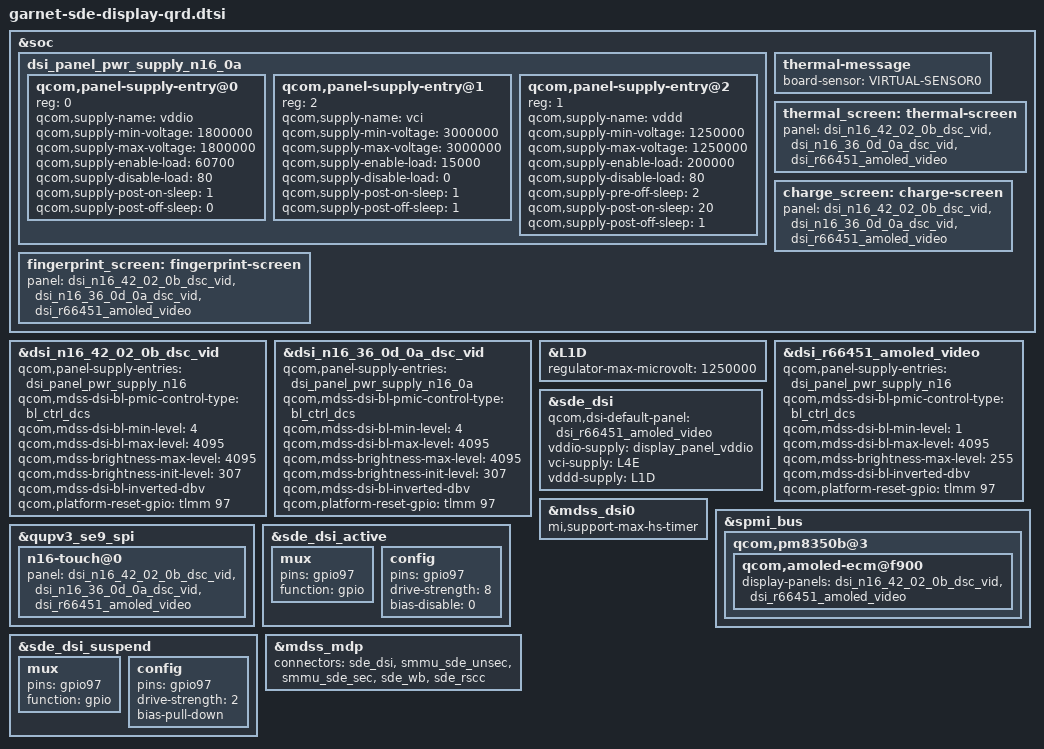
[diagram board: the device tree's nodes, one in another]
#include "parrot-sde-display.dtsi"

&soc {
	dsi_panel_pwr_supply_n16_0a: dsi_panel_pwr_supply_n16_0a {
		#address-cells = <1>;
		#size-cells = <0>;
		qcom,panel-supply-entry@0 {
			reg = <0>;
			qcom,supply-name = "vddio";
			qcom,supply-min-voltage = <1800000>;
			qcom,supply-max-voltage = <1800000>;
			qcom,supply-enable-load = <60700>;
			qcom,supply-disable-load = <80>;
			qcom,supply-post-on-sleep = <1>;
			qcom,supply-post-off-sleep = <0>;
		};
		qcom,panel-supply-entry@1 {
			reg = <2>;
			qcom,supply-name = "vci";
			qcom,supply-min-voltage = <3000000>;
			qcom,supply-max-voltage = <3000000>;
			qcom,supply-enable-load = <15000>;
			qcom,supply-disable-load = <0>;
			qcom,supply-post-on-sleep = <1>;
			qcom,supply-post-off-sleep = <1>;
		};
		qcom,panel-supply-entry@2 {
			reg = <1>;
			qcom,supply-name = "vddd";
			qcom,supply-min-voltage = <1250000>;
			qcom,supply-max-voltage = <1250000>;
			qcom,supply-enable-load = <200000>;
			qcom,supply-disable-load = <80>;
			qcom,supply-pre-off-sleep = <2>;
			qcom,supply-post-on-sleep = <20>;
			qcom,supply-post-off-sleep = <1>;
		};
	};
};

&dsi_n16_42_02_0b_dsc_vid {
	qcom,panel-supply-entries = <&dsi_panel_pwr_supply_n16>;
	qcom,mdss-dsi-bl-pmic-control-type = "bl_ctrl_dcs";
	qcom,mdss-dsi-bl-min-level = <4>;
	qcom,mdss-dsi-bl-max-level = <4095>;
	qcom,mdss-brightness-max-level = <4095>;
	qcom,mdss-brightness-init-level = <307>;
	qcom,mdss-dsi-bl-inverted-dbv;
	qcom,platform-reset-gpio = <&tlmm 97 0>;
};

&dsi_n16_36_0d_0a_dsc_vid {
	qcom,panel-supply-entries = <&dsi_panel_pwr_supply_n16_0a>;
	qcom,mdss-dsi-bl-pmic-control-type = "bl_ctrl_dcs";
	qcom,mdss-dsi-bl-min-level = <4>;
	qcom,mdss-dsi-bl-max-level = <4095>;
	qcom,mdss-brightness-max-level = <4095>;
	qcom,mdss-brightness-init-level = <307>;
	qcom,mdss-dsi-bl-inverted-dbv;
	qcom,platform-reset-gpio = <&tlmm 97 0>;
};

&L1D {
    regulator-max-microvolt = <1250000>;
};

&dsi_r66451_amoled_video {
	qcom,panel-supply-entries = <&dsi_panel_pwr_supply_n16>;
	qcom,mdss-dsi-bl-pmic-control-type = "bl_ctrl_dcs";
	qcom,mdss-dsi-bl-min-level = <1>;
	qcom,mdss-dsi-bl-max-level = <4095>;
	qcom,mdss-brightness-max-level = <255>;
	qcom,mdss-dsi-bl-inverted-dbv;
	qcom,platform-reset-gpio = <&tlmm 97 0>;
};

&sde_dsi {
	qcom,dsi-default-panel = <&dsi_r66451_amoled_video>;
	vddio-supply = <&display_panel_vddio>;
	vci-supply = <&L4E>;
	vddd-supply = <&L1D>;
};

&mdss_dsi0 {
	mi,support-max-hs-timer;
};

&spmi_bus {
	qcom,pm8350b@3 {
		qcom,amoled-ecm@f900 {
			display-panels = <&dsi_n16_42_02_0b_dsc_vid
					&dsi_r66451_amoled_video>;
		};
	};
};

&qupv3_se9_spi {
	n16-touch@0 {
		panel = <&dsi_n16_42_02_0b_dsc_vid
			&dsi_n16_36_0d_0a_dsc_vid
			&dsi_r66451_amoled_video>;
	};
};

&sde_dsi_active {
	mux {
		pins = "gpio97";
		function = "gpio";
	};

	config {
		pins = "gpio97";
		drive-strength = <8>;   /* 8 mA */
		bias-disable = <0>;   /* no pull */
	};
};

&sde_dsi_suspend {
	mux {
		pins = "gpio97";
		function = "gpio";
	};

	config {
		pins = "gpio97";
		drive-strength = <2>;   /* 2 mA */
		bias-pull-down;         /* PULL DOWN */
	};
};

&soc {
	thermal-message {
		board-sensor = "VIRTUAL-SENSOR0";
	};
	thermal_screen: thermal-screen {
		panel = <&dsi_n16_42_02_0b_dsc_vid
		&dsi_n16_36_0d_0a_dsc_vid
		&dsi_r66451_amoled_video>;
	};
	charge_screen: charge-screen {
		panel = <&dsi_n16_42_02_0b_dsc_vid
		&dsi_n16_36_0d_0a_dsc_vid
		&dsi_r66451_amoled_video>;
	};
	fingerprint_screen: fingerprint-screen {
		panel = <&dsi_n16_42_02_0b_dsc_vid
		&dsi_n16_36_0d_0a_dsc_vid
		&dsi_r66451_amoled_video>;
	};
};

&mdss_mdp {
        connectors = <&sde_dsi &smmu_sde_unsec &smmu_sde_sec &sde_wb &sde_rscc>;
};

